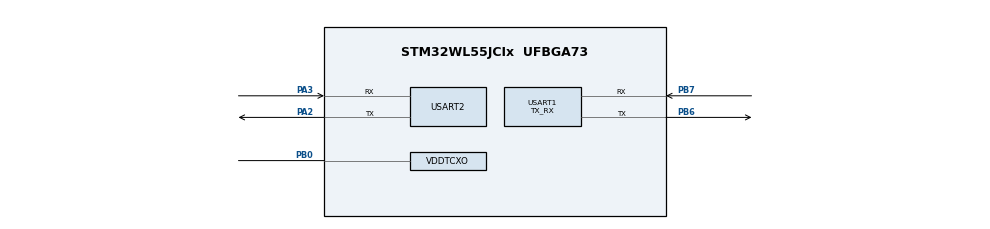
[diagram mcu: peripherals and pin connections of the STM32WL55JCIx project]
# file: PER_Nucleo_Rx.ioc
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FREERTOS.INCLUDE_vTaskCleanUpResources=1
FREERTOS.INCLUDE_xTaskResumeFromISR=0
FREERTOS.Tasks01=defaultTask,24,128,StartDefaultTask,Default,NULL,Dynamic,NULL,NULL
FREERTOS.configENABLE_BACKWARD_COMPATIBILITY=0
FREERTOS.configTOTAL_HEAP_SIZE=6144
FREERTOS.configUSE_NEWLIB_REENTRANT=1
Mcu.Family=STM32WL
Mcu.Name=STM32WL55JCIx
Mcu.Package=UFBGA73
Mcu.UserConstants=RTC_PREDIV_A,((1<<(15-RTC_N_PREDIV_S))-1);RTC_N_PREDIV_S,10;RTC_PREDIV_S,((1<<RTC_N_PREDIV_S)-1)
NVIC.PriorityGroup=NVIC_PRIORITYGROUP_4
NVIC.SUBGHZ_Radio_IRQn=true\:5\:0\:false\:false\:true\:true\:true\:true\:true
NVIC.TimeBase=None
OSC_IN.Mode=HSE-TCXO
OSC_IN.Signal=RCC_OSC_IN
PA2.Mode=Asynchronous
PA2.Signal=USART2_TX
PA3.Mode=Asynchronous
PA3.Signal=USART2_RX
PB0-VDD_TCXO.Mode=HSE-TCXO
PB0-VDD_TCXO.Signal=VDDTCXO
PB6.Mode=Asynchronous
PB6.Signal=USART1_TX
PB7.Mode=Asynchronous
PB7.Signal=USART1_RX
PC14-OSC32_IN.Mode=LSE-External-Oscillator
PC14-OSC32_IN.Signal=RCC_OSC32_IN
PC15-OSC32_OUT.Mode=LSE-External-Oscillator
PC15-OSC32_OUT.Signal=RCC_OSC32_OUT
ProjectManager.HeapSize=0x200
ProjectManager.StackSize=0x400
ProjectManager.TargetToolchain=STM32CubeIDE
RCC.AHBFreq_Value=48000000
RCC.APB1Freq_Value=48000000
RCC.APB1TimFreq_Value=48000000
RCC.APB2Freq_Value=48000000
RCC.APB2TimFreq_Value=48000000
RCC.APB3Freq_Value=48000000
RCC.CortexFreq_Value=48000000
RCC.FLatency=FLASH_LATENCY_2
RCC.HCLKFreq_Value=48000000
RCC.HSE_VALUE=8000000
RCC.HSI_VALUE=16000000
RCC.LSE_VALUE=32768
RCC.MSIClockRange=RCC_MSIRANGE_11
RCC.PWR_Regulator_Voltage_Scale=PWR_REGULATOR_VOLTAGE_SCALE1
RCC.RTCClockSelection=RCC_RTCCLKSOURCE_LSE
RCC.SYSCLKFreq_VALUE=48000000
RCC.VCOOutputFreq_Value=384000000
SUBGHZ.BaudratePrescaler=SUBGHZSPI_BAUDRATEPRESCALER_4
SUBGHZ_PHY.Activate_RADIO_BOARD_INTERFACE=Bsp
SUBGHZ_PHY.REGION=REGION_EU433
SUBGHZ_PHY.SUBGHZ_APPLICATION=SUBGHZ_USER_APPLICATION
SUBGHZ_PHY.USE_LPM=false
SUBGHZ_PHY.USE_RTC=false
USART1.Mode=MODE_TX_RX
USART1.VirtualMode-Asynchronous=VM_ASYNC
USART2.VirtualMode-Asynchronous=VM_ASYNC
VP_ADV_TRACE_VS_ADV_TRACE.Mode=ADV_TRACE_Enabled
VP_FREERTOS_VS_CMSIS_V2.Mode=CMSIS_V2
VP_MISC_VS_MISC.Mode=MISC_Enabled
VP_SUBGHZ_PHY_VS_SubGhzPhy.Mode=SubGhzPhy_Enabled
VP_SUBGHZ_VS_SUBGHZ.Mode=SUBGHZ_Activate
VP_SYS_VS_None.Mode=None
VP_TIMER_VS_TIMER.Mode=TIMER_Enabled
VP_TINY_LPM_VS_TINY_LPM.Mode=TINY_LPM_Enabled
board=custom

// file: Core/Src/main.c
/* USER CODE BEGIN Header */
/**
  ******************************************************************************
  * @file           : main.c
  * @brief          : Main program body
  ******************************************************************************
  * @attention
  *
  * Copyright (c) 2022 STMicroelectronics.
  * All rights reserved.
  *
  * This software is licensed under terms that can be found in the LICENSE file
  * in the root directory of this software component.
  * If no LICENSE file comes with this software, it is provided AS-IS.
  *
  ******************************************************************************
  */
/* USER CODE END Header */
#include "main.h"
#include "cmsis_os.h"
#include "app_subghz_phy.h"
#include "usart.h"
#include "gpio.h"

/* USER CODE BEGIN Includes */
#include "subghz.h"
#include "devices_conf.h"
/* USER CODE END Includes */

void SystemClock_Config(void);
void MX_FREERTOS_Init(void);

int main(void)
{

  /* MCU Configuration--------------------------------------------------------*/

  /* Reset of all peripherals, Initializes the Flash interface and the Systick. */
  HAL_Init();

  /* Configure the system clock */
  SystemClock_Config();

  /* Initialize all configured peripherals */
  MX_GPIO_Init();
  MX_SUBGHZ_Init();
  MX_USART1_UART_Init();
  MX_USART2_UART_Init();
  /* USER CODE BEGIN 2 */

  /* Wait for configuration values */
  DevConf_Rx_ReceiveConfValues();

  /* USER CODE END 2 */

  /* Init scheduler */
  osKernelInitialize();  /* Call init function for freertos objects (in freertos.c) */
  MX_FREERTOS_Init();

  /* Start scheduler */
  osKernelStart();

  /* We should never get here as control is now taken by the scheduler */
  /* Infinite loop */
  while (1)
  {

  }
}

void SystemClock_Config(void)
{
  RCC_OscInitTypeDef RCC_OscInitStruct = {0};
  RCC_ClkInitTypeDef RCC_ClkInitStruct = {0};

  /** Configure LSE Drive Capability
  */
  HAL_PWR_EnableBkUpAccess();
  __HAL_RCC_LSEDRIVE_CONFIG(RCC_LSEDRIVE_LOW);

  /** Configure the main internal regulator output voltage
  */
  __HAL_PWR_VOLTAGESCALING_CONFIG(PWR_REGULATOR_VOLTAGE_SCALE1);

  /** Initializes the CPU, AHB and APB busses clocks
  */
  RCC_OscInitStruct.OscillatorType = RCC_OSCILLATORTYPE_LSE|RCC_OSCILLATORTYPE_MSI;
  RCC_OscInitStruct.LSEState = RCC_LSE_ON;
  RCC_OscInitStruct.MSIState = RCC_MSI_ON;
  RCC_OscInitStruct.MSICalibrationValue = RCC_MSICALIBRATION_DEFAULT;
  RCC_OscInitStruct.MSIClockRange = RCC_MSIRANGE_11;
  RCC_OscInitStruct.PLL.PLLState = RCC_PLL_NONE;
  if (HAL_RCC_OscConfig(&RCC_OscInitStruct) != HAL_OK)
  {
    Error_Handler();
  }

  /** Configure the SYSCLKSource, HCLK, PCLK1 and PCLK2 clocks dividers
  */
  RCC_ClkInitStruct.ClockType = RCC_CLOCKTYPE_HCLK3|RCC_CLOCKTYPE_HCLK
                              |RCC_CLOCKTYPE_SYSCLK|RCC_CLOCKTYPE_PCLK1
                              |RCC_CLOCKTYPE_PCLK2;
  RCC_ClkInitStruct.SYSCLKSource = RCC_SYSCLKSOURCE_MSI;
  RCC_ClkInitStruct.AHBCLKDivider = RCC_SYSCLK_DIV1;
  RCC_ClkInitStruct.APB1CLKDivider = RCC_HCLK_DIV1;
  RCC_ClkInitStruct.APB2CLKDivider = RCC_HCLK_DIV1;
  RCC_ClkInitStruct.AHBCLK3Divider = RCC_SYSCLK_DIV1;

  if (HAL_RCC_ClockConfig(&RCC_ClkInitStruct, FLASH_LATENCY_2) != HAL_OK)
  {
    Error_Handler();
  }
}

void Error_Handler(void)
{
  __disable_irq();
  while (1)
  {
  }
}

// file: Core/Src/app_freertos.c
/* USER CODE BEGIN Header */
/**
  ******************************************************************************
  * File Name          : app_freertos.c
  * Description        : Code for freertos applications
  ******************************************************************************
  * @attention
  *
  * Copyright (c) 2022 STMicroelectronics.
  * All rights reserved.
  *
  * This software is licensed under terms that can be found in the LICENSE file
  * in the root directory of this software component.
  * If no LICENSE file comes with this software, it is provided AS-IS.
  *
  ******************************************************************************
  */
/* USER CODE END Header */

#include "FreeRTOS.h"
#include "task.h"
#include "main.h"
#include "cmsis_os.h"

#include "app_subghz_phy.h"

/* Definitions for defaultTask */
osThreadId_t defaultTaskHandle;
const osThreadAttr_t defaultTask_attributes = {
  .name = "defaultTask",
  .priority = (osPriority_t) osPriorityNormal,
  .stack_size = 128 * 4
};

void StartDefaultTask(void *argument);

void MX_FREERTOS_Init(void); /* (MISRA C 2004 rule 8.1) */

void MX_FREERTOS_Init(void) {

  /* Create the thread(s) */
  /* creation of defaultTask */
  defaultTaskHandle = osThreadNew(StartDefaultTask, NULL, &defaultTask_attributes);

}

void StartDefaultTask(void *argument)
{
  /* init code for SubGHz_Phy */
  MX_SubGHz_Phy_Init();
  /* USER CODE BEGIN StartDefaultTask */
  /* Infinite loop */
  for(;;)
  {
	  osThreadFlagsWait(1, osFlagsWaitAll, osWaitForever);
  }
  /* USER CODE END StartDefaultTask */
}
